# CPU_SCS register map
Vendor: Texas Instruments
Peripheral module from a debugger description file (folder CC2652).
Registers are 32-bit, read-write, reset 0x0 unless marked. A register's access mark holds for its fields unless they carry their own. Offsets are as the file gives them; lines under a group give offsets from that group; [hi:lo] are bit positions; {n}, {i} and the like mark numbered series; 'fields as' and 'values as' point back to an identical list; <NAME> marks a mode.

## CPU_SCS (part 1 of 2) — Cortex-M's System Control Space (SCS)
0x04 ICTR ro reset 0x1 — Interrupt Control Type Read this register to see the number of interrupt lines that the NVIC supports.
  [2:0] INTLINESNUM — Total number of interrupt lines in groups of 32. 0: 0...32 1: 33...64 2: 65...96 3: 97...128 4: 129...160 5: 161...192 6: 193...224 7: 225...256
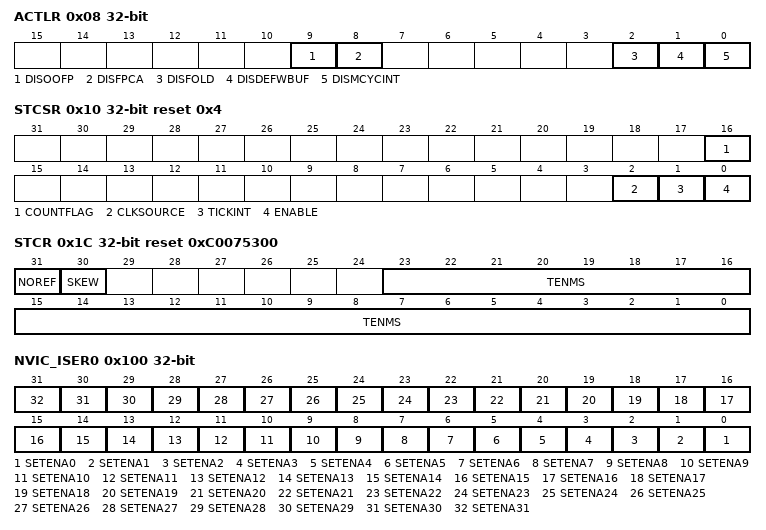
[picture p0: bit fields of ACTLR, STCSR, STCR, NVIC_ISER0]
0x08 ACTLR — Auxiliary Control This register is used to disable certain aspects of functionality within the processor
  [9] DISOOFP — Disables floating point instructions completing out of order with respect to integer instructions.
  [8] DISFPCA — Disable automatic update of CONTROL.FPCA
  [2] DISFOLD — Disables folding of IT instruction.
  [1] DISDEFWBUF — Disables write buffer use during default memory map accesses. This causes all bus faults to be precise bus faults but decreases the performance of the processor because the stores to memory have to complete before the next instruction can be executed.
  [0] DISMCYCINT — Disables interruption of multi-cycle instructions. This increases the interrupt latency of the processor becuase LDM/STM completes before interrupt stacking occurs.
0x10 STCSR access per field reset 0x4 — SysTick Control and Status This register enables the SysTick features and returns status flags related to SysTick.
  [16] COUNTFLAG ro — Returns 1 if timer counted to 0 since last time this was read. Clears on read by application of any part of the SysTick Control and Status Register. If read by the debugger using the DAP, this bit is cleared on read-only if the MasterType bit in the **AHB-AP** Control Register is set to 0. Otherwise, COUNTFLAG is not changed by the debugger read.
  [2] CLKSOURCE ro — Clock source: 0: External reference clock. 1: Core clock External clock is not available in this device. Writes to this field will be ignored.
  [1] TICKINT rw — 0: Counting down to zero does not pend the SysTick handler. Software can use COUNTFLAG to determine if the SysTick handler has ever counted to zero. 1: Counting down to zero pends the SysTick handler.
  [0] ENABLE rw — Enable SysTick counter 0: Counter disabled 1: Counter operates in a multi-shot way. That is, counter loads with the Reload value STRVR.RELOAD and then begins counting down. On reaching 0, it sets COUNTFLAG to 1 and optionally pends the SysTick handler, based on TICKINT. It then loads STRVR.RELOAD again, and begins counting.
0x14 STRVR — SysTick Reload Value This register is used to specify the start value to load into the current value register STCVR.CURRENT when the counter reaches 0. It can be any value between 1 and 0x00FFFFFF. A start value of 0 is possible, but has no effect because the SysTick interrupt and STCSR.COUNTFLAG are activated when counting from 1 to 0.
  [23:0] RELOAD — Value to load into the SysTick Current Value Register STCVR.CURRENT when the counter reaches 0.
0x18 STCVR — SysTick Current Value Read from this register returns the current value of SysTick counter. Writing to this register resets the SysTick counter (as well as STCSR.COUNTFLAG).
  [23:0] CURRENT — Current value at the time the register is accessed. No read-modify-write protection is provided, so change with care. Writing to it with any value clears the register to 0. Clearing this register also clears STCSR.COUNTFLAG.
0x1C STCR ro reset 0xC0075300 — SysTick Calibration Value Used to enable software to scale to any required speed using divide and multiply.
  [31] NOREF — Reads as one. Indicates that no separate reference clock is provided.
  [30] SKEW — Reads as one. The calibration value is not exactly 10ms because of clock frequency. This could affect its suitability as a software real time clock.
  [23:0] TENMS — An optional Reload value to be used for 10ms (100Hz) timing, subject to system clock skew errors. The value read is valid only when core clock is at 48MHz.
0x100 NVIC_ISER0 — Irq 0 to 31 Set Enable This register is used to enable interrupts and determine which interrupts are currently enabled.
  [n] SETENA{n} (n=0..31) — Writing 0 to this bit has no effect, writing 1 to this bit enables the interrupt number {n} (See EVENT:CPUIRQSEL{n}.EV for details). Reading the bit returns its current enable state.
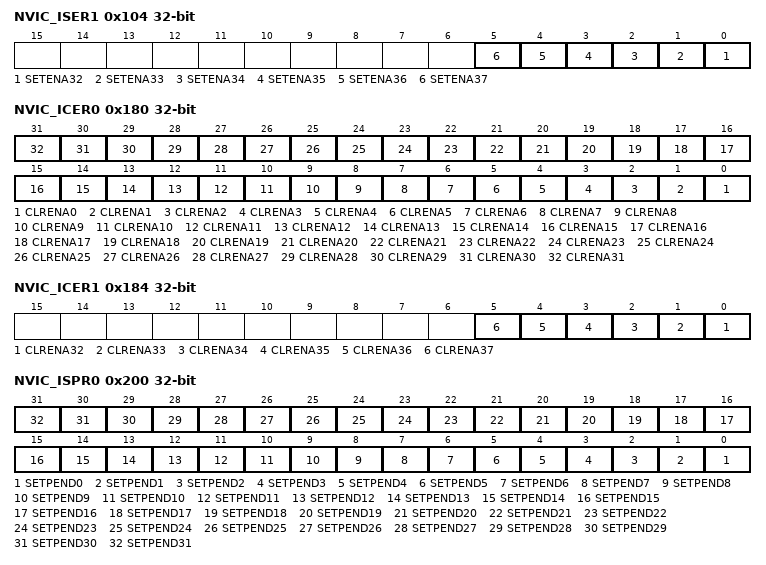
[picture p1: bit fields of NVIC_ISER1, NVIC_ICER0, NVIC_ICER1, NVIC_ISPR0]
0x104 NVIC_ISER1 — Irq 32 to 63 Set Enable This register is used to enable interrupts and determine which interrupts are currently enabled.
  [n-32] SETENA{n} (n=32..37) — Writing 0 to this bit has no effect, writing 1 to this bit enables the interrupt number {n} (See EVENT:CPUIRQSEL{n}.EV for details). Reading the bit returns its current enable state.
0x180 NVIC_ICER0 — Irq 0 to 31 Clear Enable This register is used to disable interrupts and determine which interrupts are currently enabled.
  [n] CLRENA{n} (n=0..31) — Writing 0 to this bit has no effect, writing 1 to this bit disables the interrupt number {n} (See EVENT:CPUIRQSEL{n}.EV for details). Reading the bit returns its current enable state.
0x184 NVIC_ICER1 — Irq 32 to 63 Clear Enable This register is used to disable interrupts and determine which interrupts are currently enabled.
  [n-32] CLRENA{n} (n=32..37) — Writing 0 to this bit has no effect, writing 1 to this bit disables the interrupt number {n} (See EVENT:CPUIRQSEL{n}.EV for details). Reading the bit returns its current enable state.
0x200 NVIC_ISPR0 — Irq 0 to 31 Set Pending This register is used to force interrupts into the pending state and determine which interrupts are currently pending.
  [n] SETPEND{n} (n=0..31) — Writing 0 to this bit has no effect, writing 1 to this bit pends the interrupt number {n} (See EVENT:CPUIRQSEL{n}.EV for details). Reading the bit returns its current state.
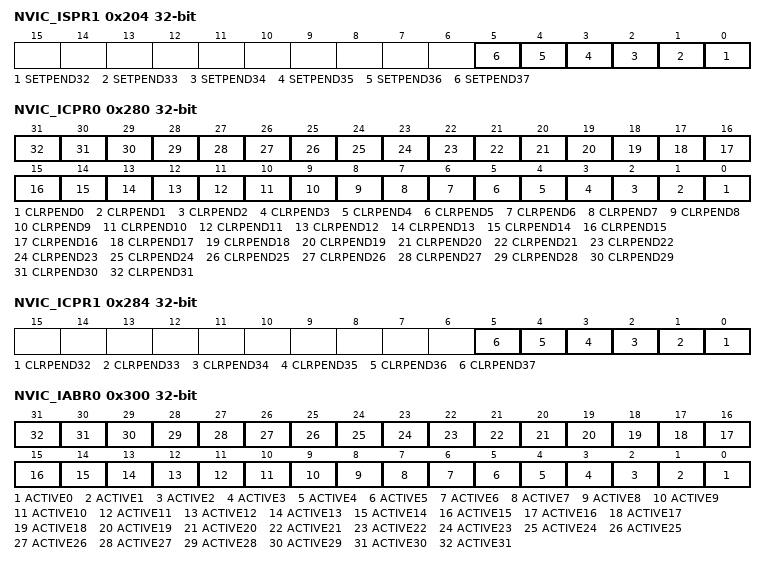
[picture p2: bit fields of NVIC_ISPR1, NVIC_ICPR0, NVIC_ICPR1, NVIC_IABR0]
0x204 NVIC_ISPR1 — Irq 32 to 63 Set Pending This register is used to force interrupts into the pending state and determine which interrupts are currently pending.
  [n-32] SETPEND{n} (n=32..37) — Writing 0 to this bit has no effect, writing 1 to this bit pends the interrupt number {n} (See EVENT:CPUIRQSEL{n}.EV for details). Reading the bit returns its current state.
0x280 NVIC_ICPR0 — Irq 0 to 31 Clear Pending This register is used to clear pending interrupts and determine which interrupts are currently pending.
  [n] CLRPEND{n} (n=0..31) — Writing 0 to this bit has no effect, writing 1 to this bit clears the corresponding pending interrupt {n} (See EVENT:CPUIRQSEL{n}.EV for details). Reading the bit returns its current state.
0x284 NVIC_ICPR1 — Irq 32 to 63 Clear Pending This register is used to clear pending interrupts and determine which interrupts are currently pending.
  [n-32] CLRPEND{n} (n=32..37) — Writing 0 to this bit has no effect, writing 1 to this bit clears the corresponding pending interrupt {n} (See EVENT:CPUIRQSEL{n}.EV for details). Reading the bit returns its current state.
0x300 NVIC_IABR0 ro — Irq 0 to 31 Active Bit This register is used to determine which interrupts are active. Each flag in the register corresponds to one interrupt.
  [n] ACTIVE{n} (n=0..31) — Reading 0 from this bit implies that interrupt line {n} is not active. Reading 1 from this bit implies that the interrupt line {n} is active (See EVENT:CPUIRQSEL{n}.EV for details).
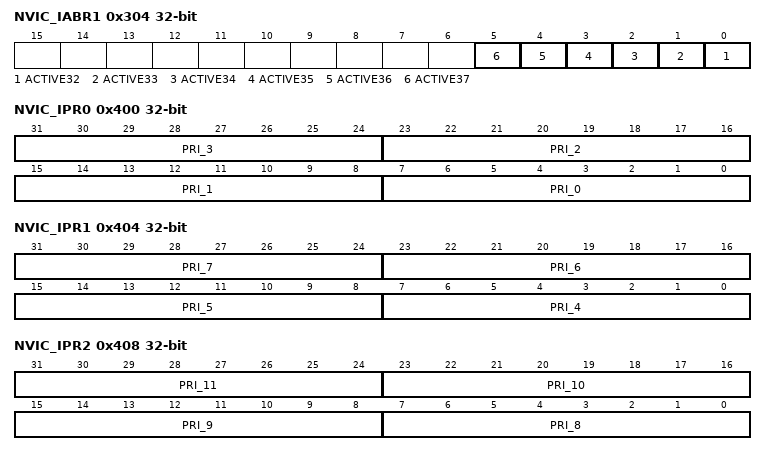
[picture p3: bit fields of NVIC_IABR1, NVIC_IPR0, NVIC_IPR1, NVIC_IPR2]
0x304 NVIC_IABR1 ro — Irq 32 to 63 Active Bit This register is used to determine which interrupts are active. Each flag in the register corresponds to one interrupt.
  [n-32] ACTIVE{n} (n=32..37) — Reading 0 from this bit implies that interrupt line {n} is not active. Reading 1 from this bit implies that the interrupt line {n} is active (See EVENT:CPUIRQSEL{n}.EV for details).
0x400 NVIC_IPR0 — Irq 0 to 3 Priority This register is used to assign a priority from 0 to 255 to each of the available interrupts. 0 is the highest priority, and 255 is the lowest. The interpretation of the Interrupt Priority Registers changes based on the setting in AIRCR.PRIGROUP.
  [8n+7:8n] PRI_{n} (n=0..3) — Priority of interrupt {n} (See EVENT:CPUIRQSEL{n}.EV for details).
0x404 NVIC_IPR1 — Irq 4 to 7 Priority This register is used to assign a priority from 0 to 255 to each of the available interrupts. 0 is the highest priority, and 255 is the lowest. The interpretation of the Interrupt Priority Registers changes based on the setting in AIRCR.PRIGROUP.
  [8n-25:8n-32] PRI_{n} (n=4..7) — Priority of interrupt {n} (See EVENT:CPUIRQSEL{n}.EV for details).
0x408 NVIC_IPR2 — Irq 8 to 11 Priority This register is used to assign a priority from 0 to 255 to each of the available interrupts. 0 is the highest priority, and 255 is the lowest. The interpretation of the Interrupt Priority Registers changes based on the setting in AIRCR.PRIGROUP.
  [8n-57:8n-64] PRI_{n} (n=8..11) — Priority of interrupt {n} (See EVENT:CPUIRQSEL{n}.EV for details).
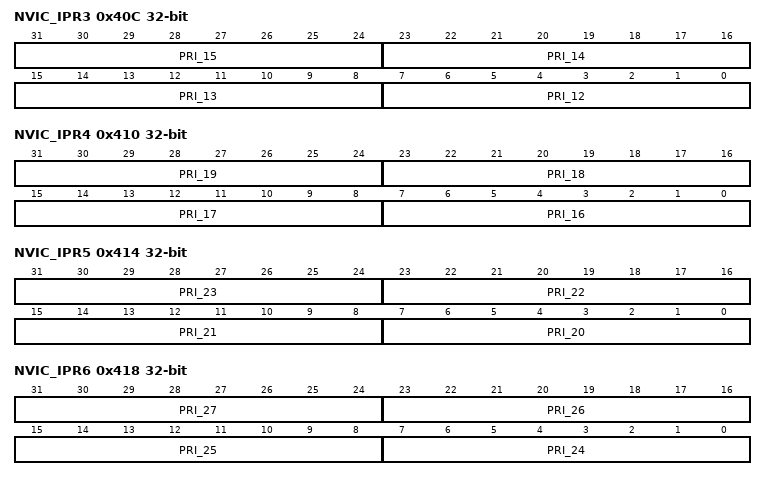
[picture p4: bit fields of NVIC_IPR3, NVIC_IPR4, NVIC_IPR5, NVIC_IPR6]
0x40C NVIC_IPR3 — Irq 12 to 15 Priority This register is used to assign a priority from 0 to 255 to each of the available interrupts. 0 is the highest priority, and 255 is the lowest. The interpretation of the Interrupt Priority Registers changes based on the setting in AIRCR.PRIGROUP.
  [8n-89:8n-96] PRI_{n} (n=12..15) — Priority of interrupt {n} (See EVENT:CPUIRQSEL{n}.EV for details).
0x410 NVIC_IPR4 — Irq 16 to 19 Priority This register is used to assign a priority from 0 to 255 to each of the available interrupts. 0 is the highest priority, and 255 is the lowest. The interpretation of the Interrupt Priority Registers changes based on the setting in AIRCR.PRIGROUP.
  [8n-121:8n-128] PRI_{n} (n=16..19) — Priority of interrupt {n} (See EVENT:CPUIRQSEL{n}.EV for details).
0x414 NVIC_IPR5 — Irq 20 to 23 Priority This register is used to assign a priority from 0 to 255 to each of the available interrupts. 0 is the highest priority, and 255 is the lowest. The interpretation of the Interrupt Priority Registers changes based on the setting in AIRCR.PRIGROUP.
  [8n-153:8n-160] PRI_{n} (n=20..23) — Priority of interrupt {n} (See EVENT:CPUIRQSEL{n}.EV for details).
0x418 NVIC_IPR6 — Irq 24 to 27 Priority This register is used to assign a priority from 0 to 255 to each of the available interrupts. 0 is the highest priority, and 255 is the lowest. The interpretation of the Interrupt Priority Registers changes based on the setting in AIRCR.PRIGROUP.
  [8n-185:8n-192] PRI_{n} (n=24..27) — Priority of interrupt {n} (See EVENT:CPUIRQSEL{n}.EV for details).
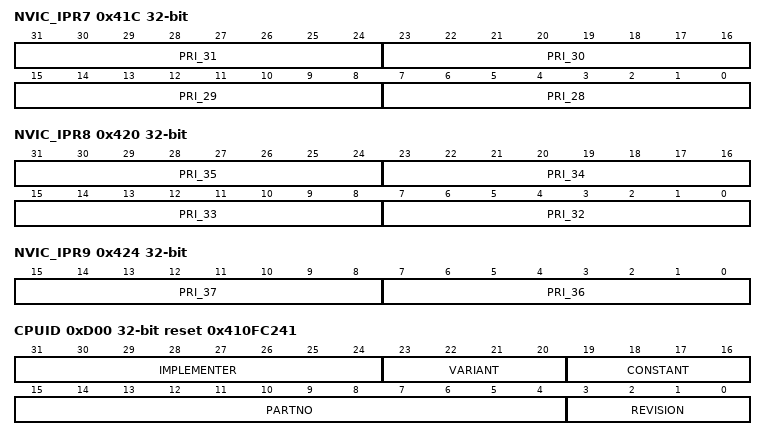
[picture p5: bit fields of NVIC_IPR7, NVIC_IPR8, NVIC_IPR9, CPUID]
0x41C NVIC_IPR7 — Irq 28 to 31 Priority This register is used to assign a priority from 0 to 255 to each of the available interrupts. 0 is the highest priority, and 255 is the lowest. The interpretation of the Interrupt Priority Registers changes based on the setting in AIRCR.PRIGROUP.
  [8n-217:8n-224] PRI_{n} (n=28..31) — Priority of interrupt {n} (See EVENT:CPUIRQSEL{n}.EV for details).
0x420 NVIC_IPR8 — Irq 32 to 35 Priority This register is used to assign a priority from 0 to 255 to each of the available interrupts. 0 is the highest priority, and 255 is the lowest. The interpretation of the Interrupt Priority Registers changes based on the setting in AIRCR.PRIGROUP.
  [8n-249:8n-256] PRI_{n} (n=32..35) — Priority of interrupt {n} (See EVENT:CPUIRQSEL{n}.EV for details).
0x424 NVIC_IPR9 — Irq 32 to 35 Priority This register is used to assign a priority from 0 to 255 to each of the available interrupts. 0 is the highest priority, and 255 is the lowest. The interpretation of the Interrupt Priority Registers changes based on the setting in AIRCR.PRIGROUP.
  [15:8] PRI_37 — Priority of interrupt 37 (See EVENT:CPUIRQSEL37.EV for details).
  [7:0] PRI_36 — Priority of interrupt 36 (See EVENT:CPUIRQSEL36.EV for details).
0xD00 CPUID ro reset 0x410FC241 — CPUID Base This register determines the ID number of the processor core, the version number of the processor core and the implementation details of the processor core.
  [31:24] IMPLEMENTER — Implementor code.
  [23:20] VARIANT — Implementation defined variant number.
  [19:16] CONSTANT — Reads as 0xF
  [15:4] PARTNO — Number of processor within family.
  [3:0] REVISION — Implementation defined revision number.
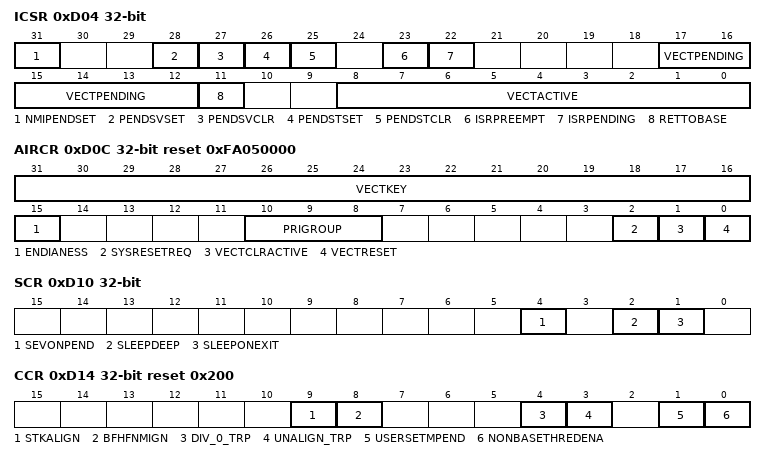
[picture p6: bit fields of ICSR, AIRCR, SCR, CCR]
0xD04 ICSR access per field — Interrupt Control State This register is used to set a pending Non-Maskable Interrupt (NMI), set or clear a pending SVC, set or clear a pending SysTick, check for pending exceptions, check the vector number of the highest priority pended exception, and check the vector number of the active exception.
  [31] NMIPENDSET rw — Set pending NMI bit. Setting this bit pends and activates an NMI. Because NMI is the highest-priority interrupt, it takes effect as soon as it registers. 0: No action 1: Set pending NMI
  [28] PENDSVSET rw — Set pending pendSV bit. 0: No action 1: Set pending PendSV
  [27] PENDSVCLR wo — Clear pending pendSV bit 0: No action 1: Clear pending pendSV
  [26] PENDSTSET rw — Set a pending SysTick bit. 0: No action 1: Set pending SysTick
  [25] PENDSTCLR wo — Clear pending SysTick bit 0: No action 1: Clear pending SysTick
  [23] ISRPREEMPT ro — This field can only be used at debug time. It indicates that a pending interrupt is to be taken in the next running cycle. If DHCSR.C_MASKINTS= 0, the interrupt is serviced. 0: A pending exception is not serviced. 1: A pending exception is serviced on exit from the debug halt state
  [22] ISRPENDING ro — Interrupt pending flag. Excludes NMI and faults. 0x0: Interrupt not pending 0x1: Interrupt pending
  [17:12] VECTPENDING ro — Pending ISR number field. This field contains the interrupt number of the highest priority pending ISR.
  [11] RETTOBASE ro — Indicates whether there are preempted active exceptions: 0: There are preempted active exceptions to execute 1: There are no active exceptions, or the currently-executing exception is the only active exception.
  [8:0] VECTACTIVE ro — Active ISR number field. Reset clears this field.
0xD08 VTOR — Vector Table Offset This register is used to relocated the vector table base address. The vector table base offset determines the offset from the bottom of the memory map. The two most significant bits and the seven least significant bits of the vector table base offset must be 0. The portion of vector table base offset that is allowed to change is TBLOFF.
  [29:7] TBLOFF — Bits 29 down to 7 of the vector table base offset.
0xD0C AIRCR access per field reset 0xFA050000 — Application Interrupt/Reset Control This register is used to determine data endianness, clear all active state information for debug or to recover from a hard failure, execute a system reset, alter the priority grouping position (binary point).
  [31:16] VECTKEY rw — Register key. Writing to this register (AIRCR) requires 0x05FA in VECTKEY. Otherwise the write value is ignored. Read always returns 0xFA05.
  [15] ENDIANESS ro — Data endianness bit
    1=BIG (Big endian); 0=LITTLE (Little endian)
  [10:8] PRIGROUP rw — Interrupt priority grouping field. This field is a binary point position indicator for creating subpriorities for exceptions that share the same pre-emption level. It divides the PRI_n field in the Interrupt Priority Registers (NVIC_IPR0, NVIC_IPR1,..., and NVIC_IPR8) into a pre-emption level and a subpriority level. The binary point is a left-of value. This means that the PRIGROUP value represents a point starting at the left of the Least Significant Bit (LSB). The lowest value might not be 0 depending on the number of bits allocated for priorities, and implementation choices.
  [2] SYSRESETREQ wo — Requests a warm reset. Setting this bit does not prevent Halting Debug from running.
  [1] VECTCLRACTIVE wo — Clears all active state information for active NMI, fault, and interrupts. It is the responsibility of the application to reinitialize the stack. This bit is for returning to a known state during debug. The bit self-clears. IPSR is not cleared by this operation. So, if used by an application, it must only be used at the base level of activation, or within a system handler whose active bit can be set.
  [0] VECTRESET wo — System Reset bit. Resets the system, with the exception of debug components. This bit is reserved for debug use and can be written to 1 only when the core is halted. The bit self-clears. Writing this bit to 1 while core is not halted may result in unpredictable behavior.
0xD10 SCR — System Control This register is used for power-management functions, i.e., signaling to the system when the processor can enter a low power state, controlling how the processor enters and exits low power states.
  [4] SEVONPEND — Send Event on Pending bit: 0: Only enabled interrupts or events can wakeup the processor, disabled interrupts are excluded 1: Enabled events and all interrupts, including disabled interrupts, can wakeup the processor. When an event or interrupt enters pending state, the event signal wakes up the processor from WFE. If the processor is not waiting for an event, the event is registered and affects the next WFE. The processor also wakes up on execution of an SEV instruction.
  [2] SLEEPDEEP — Controls whether the processor uses sleep or deep sleep as its low power mode
    1=DEEPSLEEP; 0=SLEEP
  [1] SLEEPONEXIT — Sleep on exit when returning from Handler mode to Thread mode. Enables interrupt driven applications to avoid returning to empty main application. 0: Do not sleep when returning to thread mode 1: Sleep on ISR exit
0xD14 CCR reset 0x200 — Configuration Control This register is used to enable NMI, HardFault and FAULTMASK to ignore bus fault, trap divide by zero and unaligned accesses, enable user access to the Software Trigger Interrupt Register (STIR), control entry to Thread Mode.
  [9] STKALIGN — Stack alignment bit. 0: Only 4-byte alignment is guaranteed for the SP used prior to the exception on exception entry. 1: On exception entry, the SP used prior to the exception is adjusted to be 8-byte aligned and the context to restore it is saved. The SP is restored on the associated exception return.
  [8] BFHFNMIGN — Enables handlers with priority -1 or -2 to ignore data BusFaults caused by load and store instructions. This applies to the HardFault, NMI, and FAULTMASK escalated handlers: 0: Data BusFaults caused by load and store instructions cause a lock-up 1: Data BusFaults caused by load and store instructions are ignored. Set this bit to 1 only when the handler and its data are in absolutely safe memory. The normal use of this bit is to probe system devices and bridges to detect problems.
  [4] DIV_0_TRP — Enables faulting or halting when the processor executes an SDIV or UDIV instruction with a divisor of 0: 0: Do not trap divide by 0. In this mode, a divide by zero returns a quotient of 0. 1: Trap divide by 0. The relevant Usage Fault Status Register bit is CFSR.DIVBYZERO.
  [3] UNALIGN_TRP — Enables unaligned access traps: 0: Do not trap unaligned halfword and word accesses 1: Trap unaligned halfword and word accesses. The relevant Usage Fault Status Register bit is CFSR.UNALIGNED. If this bit is set to 1, an unaligned access generates a UsageFault. Unaligned LDM, STM, LDRD, and STRD instructions always fault regardless of the value in UNALIGN_TRP.
  [1] USERSETMPEND — Enables unprivileged software access to STIR: 0: User code is not allowed to write to the Software Trigger Interrupt register (STIR). 1: User code can write the Software Trigger Interrupt register (STIR) to trigger (pend) a Main exception, which is associated with the Main stack pointer.
  [0] NONBASETHREDENA — Indicates how the processor enters Thread mode: 0: Processor can enter Thread mode only when no exception is active. 1: Processor can enter Thread mode from any level using the appropriate return value (EXC_RETURN). Exception returns occur when one of the following instructions loads a value of 0xFXXXXXXX into the PC while in Handler mode: - POP/LDM which includes loading the PC. - LDR with PC as a destination. - BX with any register. The value written to the PC is intercepted and is referred to as the EXC_RETURN value.
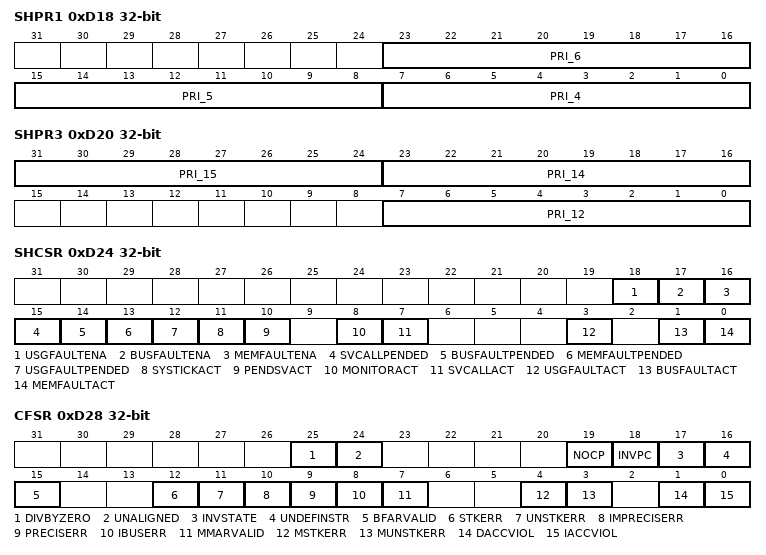
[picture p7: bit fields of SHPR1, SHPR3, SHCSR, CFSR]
0xD18 SHPR1 — System Handlers 4-7 Priority This register is used to prioritize the following system handlers: Memory manage, Bus fault, and Usage fault. System Handlers are a special class of exception handler that can have their priority set to any of the priority levels. Most can be masked on (enabled) or off (disabled). When disabled, the fault is always treated as a Hard Fault.
  [23:16] PRI_6 — Priority of system handler 6. UsageFault
  [15:8] PRI_5 — Priority of system handler 5: BusFault
  [7:0] PRI_4 — Priority of system handler 4: MemManage
0xD1C SHPR2 — System Handlers 8-11 Priority This register is used to prioritize the SVC handler. System Handlers are a special class of exception handler that can have their priority set to any of the priority levels. Most can be masked on (enabled) or off (disabled). When disabled, the fault is always treated as a Hard Fault.
  [31:24] PRI_11 — Priority of system handler 11. SVCall
0xD20 SHPR3 — System Handlers 12-15 Priority This register is used to prioritize the following system handlers: SysTick, PendSV and Debug Monitor. System Handlers are a special class of exception handler that can have their priority set to any of the priority levels. Most can be masked on (enabled) or off (disabled). When disabled, the fault is always treated as a Hard Fault.
  [31:24] PRI_15 — Priority of system handler 15. SysTick exception
  [23:16] PRI_14 — Priority of system handler 14. Pend SV
  [7:0] PRI_12 — Priority of system handler 12. Debug Monitor
0xD24 SHCSR access per field — System Handler Control and State This register is used to enable or disable the system handlers, determine the pending status of bus fault, mem manage fault, and SVC, determine the active status of the system handlers. If a fault condition occurs while its fault handler is disabled, the fault escalates to a Hard Fault.
  [18] USGFAULTENA rw — Usage fault system handler enable
    1=EN (Exception enabled); 0=DIS (Exception disabled)
  [17] BUSFAULTENA rw — Bus fault system handler enable
    1=EN (Exception enabled); 0=DIS (Exception disabled)
  [16] MEMFAULTENA rw — MemManage fault system handler enable
    1=EN (Exception enabled); 0=DIS (Exception disabled)
  [15] SVCALLPENDED ro — SVCall pending
    1=PENDING (Exception is pending.); 0=NOTPENDING (Exception is not active)
  [14] BUSFAULTPENDED ro — BusFault pending
    values as SVCALLPENDED
  [13] MEMFAULTPENDED ro — MemManage exception pending
    values as SVCALLPENDED
  [12] USGFAULTPENDED ro — Usage fault pending
    values as SVCALLPENDED
  [11] SYSTICKACT ro — SysTick active flag. 0x0: Not active 0x1: Active
    1=ACTIVE (Exception is active); 0=NOTACTIVE (Exception is not active)
  [10] PENDSVACT ro — PendSV active 0x0: Not active 0x1: Active
  [8] MONITORACT ro — Debug monitor active
    values as SYSTICKACT
  [7] SVCALLACT ro — SVCall active
    values as SYSTICKACT
  [3] USGFAULTACT ro — UsageFault exception active
    values as SYSTICKACT
  [1] BUSFAULTACT ro — BusFault exception active
    values as SYSTICKACT
  [0] MEMFAULTACT ro — MemManage exception active
    values as SYSTICKACT
0xD28 CFSR — Configurable Fault Status This register is used to obtain information about local faults. These registers include three subsections: The first byte is Memory Manage Fault Status Register (MMFSR). The second byte is Bus Fault Status Register (BFSR). The higher half-word is Usage Fault Status Register (UFSR). The flags in these registers indicate the causes of local faults. Multiple flags can be set if more than one fault occurs. These register are read/write-clear. This means that they can be read normally, but writing a 1 to any bit clears that bit. The CFSR is byte accessible. CFSR or its subregisters can be accessed as follows: The following accesses are possible to the CFSR register: - access the complete register with a word access to 0xE000ED28. - access the MMFSR with a byte access to 0xE000ED28 - access the MMFSR and BFSR with a halfword access to 0xE000ED28 - access the BFSR with a byte access to 0xE000ED29 - access the UFSR with a halfword access to 0xE000ED2A.
  [25] DIVBYZERO — When CCR.DIV_0_TRP (see Configuration Control Register on page 8-26) is enabled and an SDIV or UDIV instruction is used with a divisor of 0, this fault occurs The instruction is executed and the return PC points to it. If CCR.DIV_0_TRP is not set, then the divide returns a quotient of 0.
  [24] UNALIGNED — When CCR.UNALIGN_TRP is enabled, and there is an attempt to make an unaligned memory access, then this fault occurs. Unaligned LDM/STM/LDRD/STRD instructions always fault irrespective of the setting of CCR.UNALIGN_TRP.
  [19] NOCP — Attempt to use a coprocessor instruction. The processor does not support coprocessor instructions.
  [18] INVPC — Attempt to load EXC_RETURN into PC illegally. Invalid instruction, invalid context, invalid value. The return PC points to the instruction that tried to set the PC.
  [17] INVSTATE — Indicates an attempt to execute in an invalid EPSR state (e.g. after a BX type instruction has changed state). This includes state change after entry to or return from exception, as well as from inter-working instructions. Return PC points to faulting instruction, with the invalid state.
  [16] UNDEFINSTR — This bit is set when the processor attempts to execute an undefined instruction. This is an instruction that the processor cannot decode. The return PC points to the undefined instruction.
  [15] BFARVALID — This bit is set if the Bus Fault Address Register (BFAR) contains a valid address. This is true after a bus fault where the address is known. Other faults can clear this bit, such as a Mem Manage fault occurring later. If a Bus fault occurs that is escalated to a Hard Fault because of priority, the Hard Fault handler must clear this bit. This prevents problems if returning to a stacked active Bus fault handler whose BFAR value has been overwritten.
  [12] STKERR — Stacking from exception has caused one or more bus faults. The SP is still adjusted and the values in the context area on the stack might be incorrect. BFAR is not written.
  [11] UNSTKERR — Unstack from exception return has caused one or more bus faults. This is chained to the handler, so that the original return stack is still present. SP is not adjusted from failing return and new save is not performed. BFAR is not written.
  [10] IMPRECISERR — Imprecise data bus error. It is a BusFault, but the Return PC is not related to the causing instruction. This is not a synchronous fault. So, if detected when the priority of the current activation is higher than the Bus Fault, it only pends. Bus fault activates when returning to a lower priority activation. If a precise fault occurs before returning to a lower priority exception, the handler detects both IMPRECISERR set and one of the precise fault status bits set at the same time. BFAR is not written.
  [9] PRECISERR — Precise data bus error return.
  [8] IBUSERR — Instruction bus error flag. This flag is set by a prefetch error. The fault stops on the instruction, so if the error occurs under a branch shadow, no fault occurs. BFAR is not written.
  [7] MMARVALID — Memory Manage Address Register (MMFAR) address valid flag. A later-arriving fault, such as a bus fault, can clear a memory manage fault.. If a MemManage fault occurs that is escalated to a Hard Fault because of priority, the Hard Fault handler must clear this bit. This prevents problems on return to a stacked active MemManage handler whose MMFAR value has been overwritten.
  [4] MSTKERR — Stacking from exception has caused one or more access violations. The SP is still adjusted and the values in the context area on the stack might be incorrect. MMFAR is not written.
  [3] MUNSTKERR — Unstack from exception return has caused one or more access violations. This is chained to the handler, so that the original return stack is still present. SP is not adjusted from failing return and new save is not performed. MMFAR is not written.
  [1] DACCVIOL — Data access violation flag. Attempting to load or store at a location that does not permit the operation sets this flag. The return PC points to the faulting instruction. This error loads MMFAR with the address of the attempted access.
  [0] IACCVIOL — Instruction access violation flag. Attempting to fetch an instruction from a location that does not permit execution sets this flag. This occurs on any access to an XN region, even when the MPU is disabled or not present. The return PC points to the faulting instruction. MMFAR is not written.
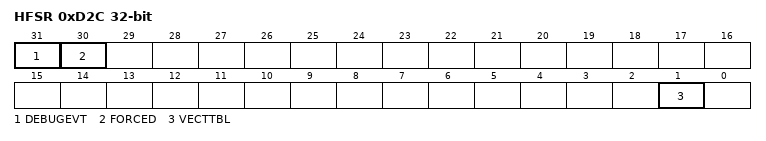
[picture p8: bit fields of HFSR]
0xD2C HFSR — Hard Fault Status This register is used to obtain information about events that activate the Hard Fault handler. This register is a write-clear register. This means that writing a 1 to a bit clears that bit.
  [31] DEBUGEVT — This bit is set if there is a fault related to debug. This is only possible when halting debug is not enabled. For monitor enabled debug, it only happens for BKPT when the current priority is higher than the monitor. When both halting and monitor debug are disabled, it only happens for debug events that are not ignored (minimally, BKPT). The Debug Fault Status Register is updated.
  [30] FORCED — Hard Fault activated because a Configurable Fault was received and cannot activate because of priority or because the Configurable Fault is disabled. The Hard Fault handler then has to read the other fault status registers to determine cause.
  [1] VECTTBL — This bit is set if there is a fault because of vector table read on exception processing (Bus Fault). This case is always a Hard Fault. The return PC points to the pre-empted instruction.
